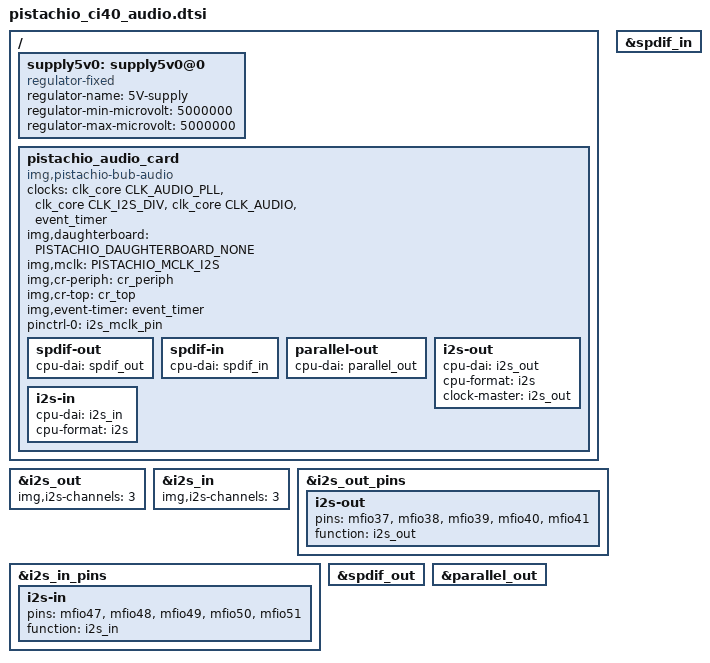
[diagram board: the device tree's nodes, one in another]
/*
 * Copyright (C) 2015 Imagination Technologies Ltd.
 *
 * This program is free software; you can redistribute it and/or modify
 * it under the terms of the GNU General Public License version 2 as
 * published by the Free Software Foundation.
 */

#include "pistachio.dtsi"
#include <dt-bindings/sound/pistachio-bub-audio.h>

/ {
	supply5v0: supply5v0@0 {
		compatible = "regulator-fixed";
		regulator-name = "5V-supply";
		regulator-min-microvolt = <5000000>;
		regulator-max-microvolt = <5000000>;
	};

	pistachio_audio_card {
		compatible = "img,pistachio-bub-audio";

		clocks = <&clk_core CLK_AUDIO_PLL>,
			 <&clk_core CLK_I2S_DIV>,
			 <&clk_core CLK_AUDIO>,
			 <&event_timer>;
		clock-names = "audio_pll", "i2s_mclk", "dac_clk", "evt_clk";

		img,daughterboard = <PISTACHIO_DAUGHTERBOARD_NONE>;
		img,mclk = <PISTACHIO_MCLK_I2S>;
		img,cr-periph = <&cr_periph>;
		img,cr-top = <&cr_top>;
		img,event-timer = <&event_timer>;

		pinctrl-names = "default";
		pinctrl-0 = <&i2s_mclk_pin>;

		spdif-out {
			cpu-dai = <&spdif_out>;
		};

		spdif-in {
			cpu-dai = <&spdif_in>;
		};

		parallel-out {
			cpu-dai = <&parallel_out>;
		};

		i2s-out {
			cpu-dai = <&i2s_out>;
			cpu-format = "i2s";
			clock-master = <&i2s_out>;
		};

		i2s-in {
			cpu-dai = <&i2s_in>;
			cpu-format = "i2s";
		};
	};
};

&i2s_out {
	img,i2s-channels = <3>;
	status = "okay";
};

&i2s_in {
	img,i2s-channels = <3>;
	status = "okay";
};

&i2s_out_pins {
	i2s-out {
		pins = "mfio37", "mfio38", "mfio39",
		       "mfio40", "mfio41";
		function = "i2s_out";
	};
};

&i2s_in_pins {
	i2s-in {
		pins = "mfio47", "mfio48", "mfio49",
		       "mfio50", "mfio51";
		function = "i2s_in";
	};
};

&spdif_out {
	status = "okay";
};

&spdif_in {
	status = "okay";
};

&parallel_out {
	status = "okay";
};
